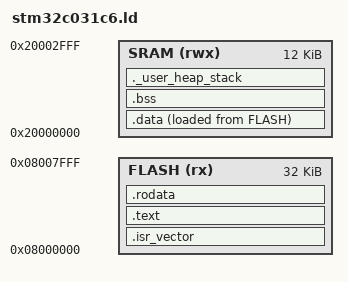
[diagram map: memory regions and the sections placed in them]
/* STM32C031C6 Linker Script */
/* Based on STM32C031C6 memory layout */

MEMORY
{
  FLASH (rx)    : ORIGIN = 0x08000000, LENGTH = 32K
  SRAM (rwx)    : ORIGIN = 0x20000000, LENGTH = 12K
}

/* Entry point */
ENTRY(Reset_Handler)

/* Minimum stack size */
_Min_Heap_Size = 0x200;
_Min_Stack_Size = 0x400;

SECTIONS
{
  /* Vector table */
  .isr_vector :
  {
    . = ALIGN(4);
    KEEP(*(.isr_vector))
    . = ALIGN(4);
  } >FLASH

  /* Program code */
  .text :
  {
    . = ALIGN(4);
    *(.text)
    *(.text*)
    *(.glue_7)
    *(.glue_7t)
    *(.eh_frame)
    
    KEEP (*(.init))
    KEEP (*(.fini))
    
    . = ALIGN(4);
    _etext = .;
  } >FLASH

  /* Constant data */
  .rodata :
  {
    . = ALIGN(4);
    *(.rodata)
    *(.rodata*)
    . = ALIGN(4);
  } >FLASH

  /* Used by startup to initialize data */
  _sidata = LOADADDR(.data);

  /* Initialized data sections */
  .data : 
  {
    . = ALIGN(4);
    _sdata = .;
    *(.data)
    *(.data*)
    
    . = ALIGN(4);
    _edata = .;
  } >SRAM AT> FLASH

  /* Uninitialized data section */
  .bss :
  {
    . = ALIGN(4);
    _sbss = .;
    __bss_start__ = _sbss;
    *(.bss)
    *(.bss*)
    *(COMMON)
    
    . = ALIGN(4);
    _ebss = .;
    __bss_end__ = _ebss;
  } >SRAM

  /* User_heap_stack section */
  ._user_heap_stack :
  {
    . = ALIGN(8);
    PROVIDE ( end = . );
    PROVIDE ( _end = . );
    . = . + _Min_Heap_Size;
    . = . + _Min_Stack_Size;
    . = ALIGN(8);
  } >SRAM
}
